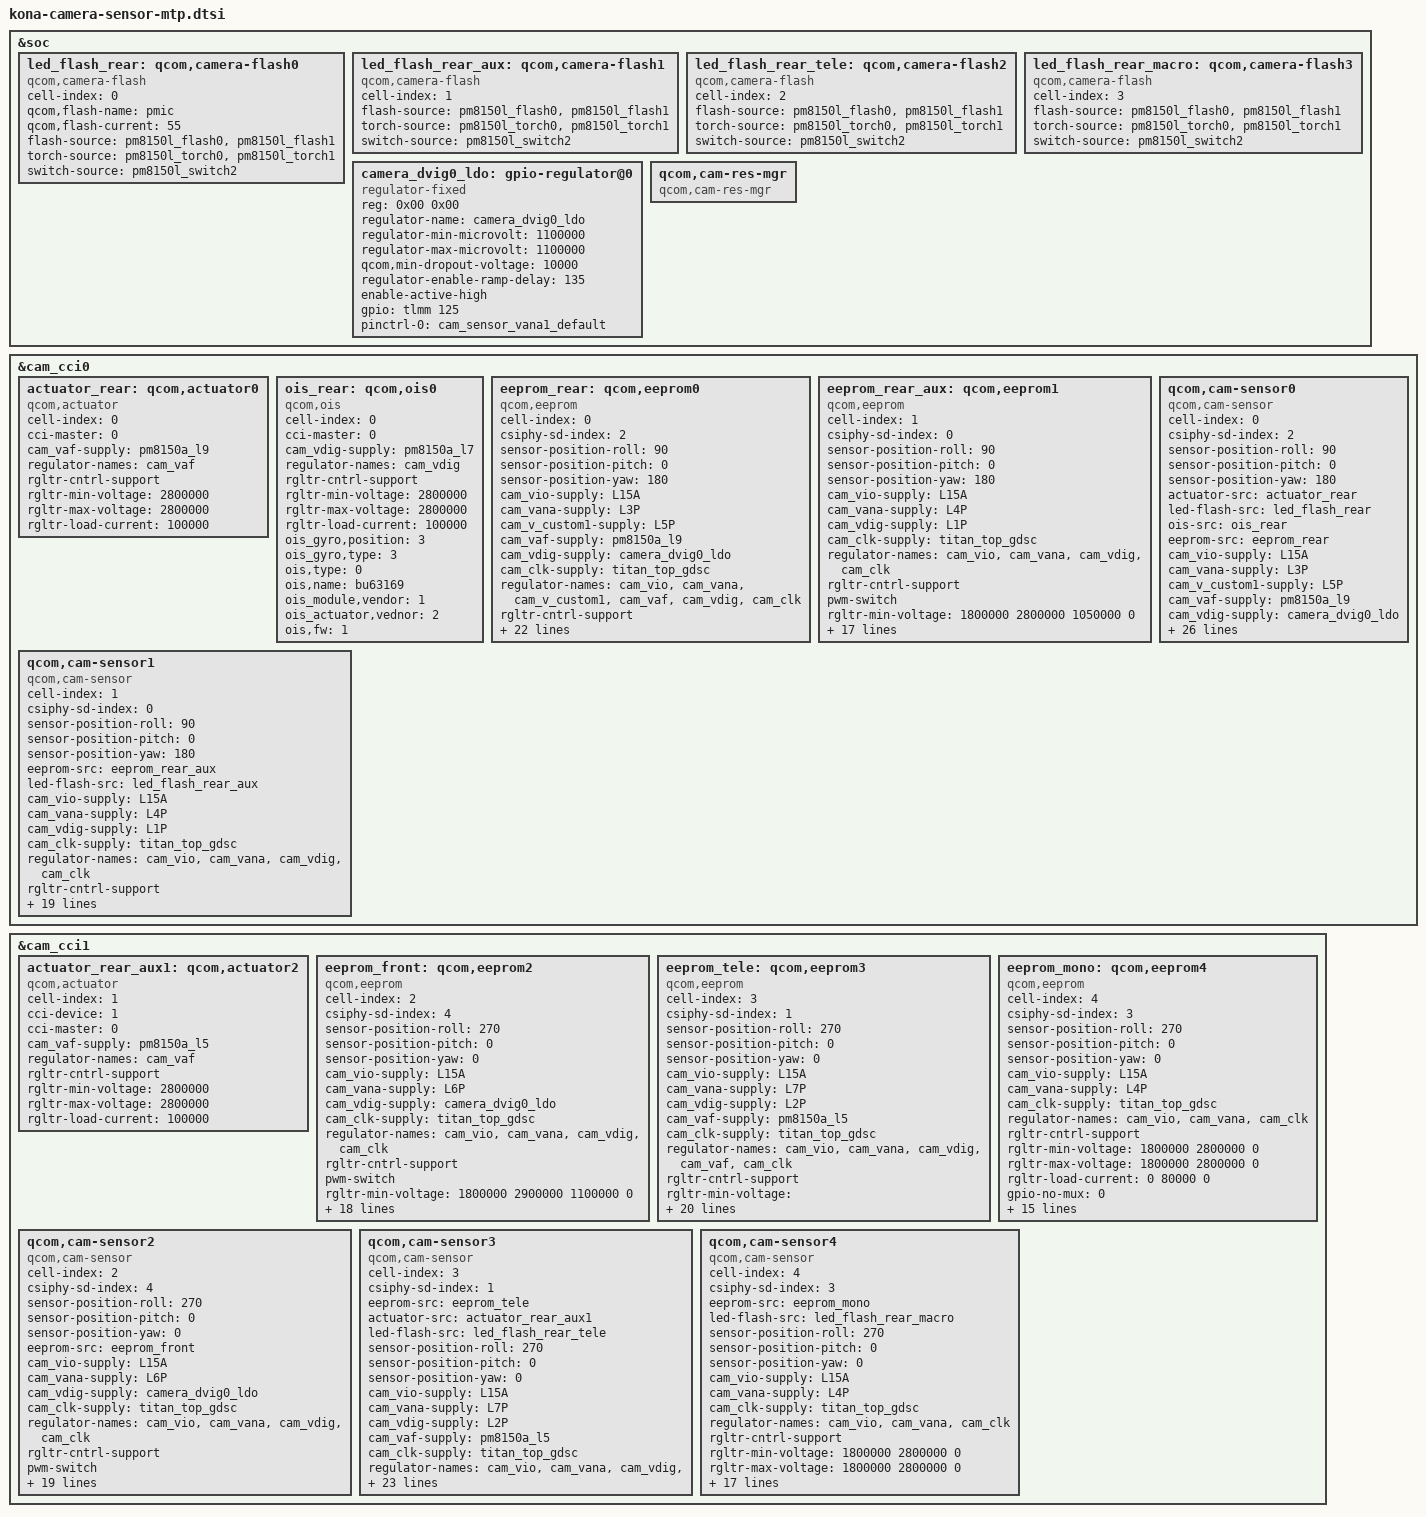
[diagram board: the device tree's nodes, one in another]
#include <dt-bindings/clock/qcom,camcc-kona.h>
/*#ifdef OPLUS_FEATURE_EDIT */
/*
&soc {
	led_flash_rear: qcom,camera-flash0 {
		cell-index = <0>;
		compatible = "qcom,camera-flash";
		flash-source = <&pm8150l_flash0 &pm8150l_flash1>;
		torch-source = <&pm8150l_torch0 &pm8150l_torch1>;
		switch-source = <&pm8150l_switch2>;
		status = "ok";
	};

	led_flash_rear_aux: qcom,camera-flash1 {
		cell-index = <1>;
		compatible = "qcom,camera-flash";
		flash-source = <&pm8150l_flash0 &pm8150l_flash1>;
		torch-source = <&pm8150l_torch0 &pm8150l_torch1>;
		switch-source = <&pm8150l_switch2>;
		status = "ok";
	};

	led_flash_triple_rear: qcom,camera-flash@4 {
		cell-index = <4>;
		compatible = "qcom,camera-flash";
		flash-source = <&pm8150l_flash0 &pm8150l_flash1>;
		torch-source = <&pm8150l_torch0 &pm8150l_torch1>;
		switch-source = <&pm8150l_switch2>;
		status = "ok";
	};

	led_flash_triple_rear_aux: qcom,camera-flash@5 {
		cell-index = <5>;
		compatible = "qcom,camera-flash";
		flash-source = <&pm8150l_flash0 &pm8150l_flash1>;
		torch-source = <&pm8150l_torch0 &pm8150l_torch1>;
		switch-source = <&pm8150l_switch2>;
		status = "ok";
	};

	led_flash_triple_rear_aux2: qcom,camera-flash@6 {
		cell-index = <6>;
		compatible = "qcom,camera-flash";
		flash-source = <&pm8150l_flash0 &pm8150l_flash1>;
		torch-source = <&pm8150l_torch0 &pm8150l_torch1>;
		switch-source = <&pm8150l_switch2>;
		status = "ok";
	};

	qcom,cam-res-mgr {
		compatible = "qcom,cam-res-mgr";
		status = "ok";
	};
};

&cam_cci0 {
	actuator_rear: qcom,actuator0 {
		cell-index = <0>;
		compatible = "qcom,actuator";
		cci-master = <0>;
		cam_vaf-supply = <&pm8150a_l7>;
		regulator-names = "cam_vaf";
		rgltr-cntrl-support;
		rgltr-min-voltage = <2856000>;
		rgltr-max-voltage = <3104000>;
		rgltr-load-current = <100000>;
	};

	actuator_rear_aux: qcom,actuator1 {
		cell-index = <1>;
		compatible = "qcom,actuator";
		cci-master = <1>;
		cam_vaf-supply = <&pm8150a_l7>;
		regulator-names = "cam_vaf";
		rgltr-cntrl-support;
		rgltr-min-voltage = <2856000>;
		rgltr-max-voltage = <3104000>;
		rgltr-load-current = <100000>;
	};

	actuator_triple_wide: qcom,actuator4 {
		cell-index = <4>;
		compatible = "qcom,actuator";
		cci-master = <0>;
		cam_vaf-supply = <&pm8150a_l7>;
		regulator-names = "cam_vaf";
		rgltr-cntrl-support;
		rgltr-min-voltage = <2856000>;
		rgltr-max-voltage = <3104000>;
		rgltr-load-current = <100000>;
	};

	actuator_triple_tele: qcom,actuator5 {
		cell-index = <5>;
		compatible = "qcom,actuator";
		cci-master = <1>;
		cam_vaf-supply = <&pm8150a_l7>;
		regulator-names = "cam_vaf";
		rgltr-cntrl-support;
		rgltr-min-voltage = <2856000>;
		rgltr-max-voltage = <3104000>;
		rgltr-load-current = <100000>;
	};

	eeprom_rear: qcom,eeprom0 {
		cell-index = <0>;
		compatible = "qcom,eeprom";
		cam_vio-supply = <&pm8009_l7>;
		cam_vana-supply = <&pm8009_l5>;
		cam_vdig-supply = <&pm8009_l1>;
		cam_clk-supply = <&titan_top_gdsc>;
		cam_vaf-supply = <&pm8150a_l7>;
		regulator-names = "cam_vio", "cam_vana", "cam_vdig",
			"cam_clk", "cam_vaf";
		rgltr-cntrl-support;
		rgltr-min-voltage = <1800000 2800000 1104000 0 2856000>;
		rgltr-max-voltage = <1800000 3000000 1104000 0 3104000>;
		rgltr-load-current = <120000 80000 1200000 0 100000>;
		gpio-no-mux = <0>;
		pinctrl-names = "cam_default", "cam_suspend";
		pinctrl-0 = <&cam_sensor_mclk0_active
				&cam_sensor_active_rear>;
		pinctrl-1 = <&cam_sensor_mclk0_suspend
				&cam_sensor_suspend_rear>;
		gpios = <&tlmm 94 0>,
			<&tlmm 93 0>;
		gpio-reset = <1>;
		gpio-req-tbl-num = <0 1>;
		gpio-req-tbl-flags = <1 0>;
		gpio-req-tbl-label = "CAMIF_MCLK0",
					"CAM_RESET0";
		sensor-position = <0>;
		sensor-mode = <0>;
		cci-master = <0>;
		status = "ok";
		clocks = <&clock_camcc CAM_CC_MCLK0_CLK>;
		clock-names = "cam_clk";
		clock-cntl-level = "turbo";
		clock-rates = <24000000>;
	};

	eeprom_rear_aux: qcom,eeprom1 {
		cell-index = <1>;
		compatible = "qcom,eeprom";
		cam_vdig-supply = <&pm8009_l2>;
		cam_vio-supply = <&pm8009_l7>;
		cam_vana-supply = <&pm8009_l6>;
		cam_clk-supply = <&titan_top_gdsc>;
		cam_vaf-supply = <&pm8150a_l7>;
		regulator-names = "cam_vio", "cam_vana", "cam_vdig",
			"cam_clk", "cam_vaf";
		rgltr-cntrl-support;
		rgltr-min-voltage = <1800000 2800000 1200000 0 2856000>;
		rgltr-max-voltage = <1800000 3000000 1200000 0 3104000>;
		rgltr-load-current = <120000 80000 1200000 0 100000>;
		gpio-no-mux = <0>;
		pinctrl-names = "cam_default", "cam_suspend";
		pinctrl-0 = <&cam_sensor_mclk1_active
				 &cam_sensor_active_rear_aux>;
		pinctrl-1 = <&cam_sensor_mclk1_suspend
				 &cam_sensor_suspend_rear_aux>;
		gpios = <&tlmm 95 0>,
			<&tlmm 92 0>;
		gpio-reset = <1>;
		gpio-req-tbl-num = <0 1>;
		gpio-req-tbl-flags = <1 0>;
		gpio-req-tbl-label = "CAMIF_MCLK1",
					"CAM_RESET1";
		sensor-position = <0>;
		sensor-mode = <0>;
		cci-master = <1>;
		status = "ok";
		clocks = <&clock_camcc CAM_CC_MCLK2_CLK>;
		clock-names = "cam_clk";
		clock-cntl-level = "turbo";
		clock-rates = <24000000>;
	};

	eeprom_triple_wide: qcom,eeprom4 {
		cell-index = <4>;
		compatible = "qcom,eeprom";
		cam_vio-supply = <&pm8009_l7>;
		cam_vana-supply = <&pm8009_l5>;
		cam_vdig-supply = <&pm8009_l1>;
		cam_clk-supply = <&titan_top_gdsc>;
		cam_vaf-supply = <&pm8150a_l7>;
		regulator-names = "cam_vio", "cam_vana", "cam_vdig",
			"cam_clk", "cam_vaf";
		rgltr-cntrl-support;
		rgltr-min-voltage = <1800000 2800000 1104000 0 2856000>;
		rgltr-max-voltage = <1800000 3000000 1104000 0 3104000>;
		rgltr-load-current = <120000 80000 1200000 0 0>;
		gpio-no-mux = <0>;
		pinctrl-names = "cam_default", "cam_suspend";
		pinctrl-0 = <&cam_sensor_mclk0_active
				&cam_sensor_active_rear>;
		pinctrl-1 = <&cam_sensor_mclk0_suspend
				&cam_sensor_suspend_rear>;
		gpios = <&tlmm 94 0>,
			<&tlmm 93 0>;
		gpio-reset = <1>;
		gpio-req-tbl-num = <0 1>;
		gpio-req-tbl-flags = <1 0>;
		gpio-req-tbl-label = "CAMIF_MCLK0",
					"CAM_RESET0";
		sensor-position = <0>;
		sensor-mode = <0>;
		cci-master = <0>;
		status = "ok";
		clocks = <&clock_camcc CAM_CC_MCLK0_CLK>;
		clock-names = "cam_clk";
		clock-cntl-level = "turbo";
		clock-rates = <24000000>;
	};

	eeprom_triple_tele: qcom,eeprom5 {
		cell-index = <5>;
		compatible = "qcom,eeprom";
		cam_vdig-supply = <&pm8009_l2>;
		cam_vio-supply = <&pm8009_l7>;
		cam_vana-supply = <&pm8009_l6>;
		cam_clk-supply = <&titan_top_gdsc>;
		cam_vaf-supply = <&pm8150a_l7>;
		regulator-names = "cam_vio", "cam_vana", "cam_vdig",
			"cam_clk", "cam_vaf";
		rgltr-cntrl-support;
		rgltr-min-voltage = <1800000 2800000 1200000 0 2856000>;
		rgltr-max-voltage = <1800000 3000000 1200000 0 3104000>;
		rgltr-load-current = <120000 80000 1200000 0 0>;
		gpio-no-mux = <0>;
		pinctrl-names = "cam_default", "cam_suspend";
		pinctrl-0 = <&cam_sensor_mclk1_active
				 &cam_sensor_active_rear_aux>;
		pinctrl-1 = <&cam_sensor_mclk1_suspend
				 &cam_sensor_suspend_rear_aux>;
		gpios = <&tlmm 95 0>,
			<&tlmm 92 0>;
		gpio-reset = <1>;
		gpio-req-tbl-num = <0 1>;
		gpio-req-tbl-flags = <1 0>;
		gpio-req-tbl-label = "CAMIF_MCLK1",
					"CAM_RESET1";
		sensor-position = <0>;
		sensor-mode = <0>;
		cci-master = <0>;
		status = "ok";
		clocks = <&clock_camcc CAM_CC_MCLK2_CLK>;
		clock-names = "cam_clk";
		clock-cntl-level = "turbo";
		clock-rates = <24000000>;
	};

	qcom,cam-sensor0 {
		cell-index = <0>;
		compatible = "qcom,cam-sensor";
		csiphy-sd-index = <0>;
		sensor-position-roll = <90>;
		sensor-position-pitch = <0>;
		sensor-position-yaw = <180>;
		actuator-src = <&actuator_rear>;
		led-flash-src = <&led_flash_rear>;
		eeprom-src = <&eeprom_rear>;
		cam_vio-supply = <&pm8009_l7>;
		cam_bob-supply = <&pm8150a_bob>;
		cam_vana-supply = <&pm8009_l5>;
		cam_vdig-supply = <&pm8009_l1>;
		cam_clk-supply = <&titan_top_gdsc>;
		regulator-names = "cam_vio", "cam_vana", "cam_vdig",
			"cam_clk", "cam_bob";
		rgltr-cntrl-support;
		pwm-switch;
		rgltr-min-voltage = <1800000 2800000 1104000 0 3008000>;
		rgltr-max-voltage = <1800000 3000000 1104000 0 3960000>;
		rgltr-load-current = <120000 80000 1200000 0 2000000>;
		gpio-no-mux = <0>;
		pinctrl-names = "cam_default", "cam_suspend";
		pinctrl-0 = <&cam_sensor_mclk0_active
				&cam_sensor_active_rear>;
		pinctrl-1 = <&cam_sensor_mclk0_suspend
				&cam_sensor_suspend_rear>;
		gpios = <&tlmm 94 0>,
			<&tlmm 93 0>;
		gpio-reset = <1>;
		gpio-req-tbl-num = <0 1>;
		gpio-req-tbl-flags = <1 0>;
		gpio-req-tbl-label = "CAMIF_MCLK0",
					"CAM_RESET0";
		sensor-mode = <0>;
		cci-master = <0>;
		status = "ok";
		clocks = <&clock_camcc CAM_CC_MCLK0_CLK>;
		clock-names = "cam_clk";
		clock-cntl-level = "turbo";
		clock-rates = <24000000>;
	};

	qcom,cam-sensor1 {
		cell-index = <1>;
		compatible = "qcom,cam-sensor";
		csiphy-sd-index = <1>;
		sensor-position-roll = <90>;
		sensor-position-pitch = <0>;
		sensor-position-yaw = <180>;
		eeprom-src = <&eeprom_rear_aux>;
		led-flash-src = <&led_flash_rear_aux>;
		actuator-src = <&actuator_rear_aux>;
		cam_bob-supply = <&pm8150a_bob>;
		cam_vdig-supply = <&pm8009_l2>;
		cam_vio-supply = <&pm8009_l7>;
		cam_vana-supply = <&pm8009_l6>;
		cam_clk-supply = <&titan_top_gdsc>;
		regulator-names = "cam_vio", "cam_vana", "cam_vdig",
			"cam_clk", "cam_bob";
		rgltr-cntrl-support;
		pwm-switch;
		rgltr-min-voltage = <1800000 2800000 1200000 0 3008000>;
		rgltr-max-voltage = <1800000 3000000 1200000 0 3960000>;
		rgltr-load-current = <120000 80000 1200000 0 2000000>;
		gpio-no-mux = <0>;
		pinctrl-names = "cam_default", "cam_suspend";
		pinctrl-0 = <&cam_sensor_mclk1_active
				&cam_sensor_active_rear_aux>;
		pinctrl-1 = <&cam_sensor_mclk1_suspend
				&cam_sensor_suspend_rear_aux>;
		gpios = <&tlmm 95 0>,
			<&tlmm 92 0>;
		gpio-reset = <1>;
		gpio-req-tbl-num = <0 1>;
		gpio-req-tbl-flags = <1 0>;
		gpio-req-tbl-label = "CAMIF_MCLK1",
					"CAM_RESET1";
		sensor-mode = <0>;
		cci-master = <1>;
		status = "ok";
		clocks = <&clock_camcc CAM_CC_MCLK1_CLK>;
		clock-names = "cam_clk";
		clock-cntl-level = "turbo";
		clock-rates = <24000000>;
	};

	qcom,cam-sensor4 {
		cell-index = <4>;
		compatible = "qcom,cam-sensor";
		csiphy-sd-index = <0>;
		sensor-position-roll = <90>;
		sensor-position-pitch = <0>;
		sensor-position-yaw = <180>;
		actuator-src = <&actuator_triple_wide>;
		led-flash-src = <&led_flash_triple_rear>;
		eeprom-src = <&eeprom_triple_wide>;
		cam_vio-supply = <&pm8009_l7>;
		cam_bob-supply = <&pm8150a_bob>;
		cam_vana-supply = <&pm8009_l5>;
		cam_vdig-supply = <&pm8009_l1>;
		cam_clk-supply = <&titan_top_gdsc>;
		regulator-names = "cam_vio", "cam_vana", "cam_vdig",
			"cam_clk", "cam_bob";
		rgltr-cntrl-support;
		pwm-switch;
		rgltr-min-voltage = <1800000 2800000 1104000 0 3008000>;
		rgltr-max-voltage = <1800000 3000000 1104000 0 3960000>;
		rgltr-load-current = <120000 80000 1200000 0 2000000>;
		gpio-no-mux = <0>;
		pinctrl-names = "cam_default", "cam_suspend";
		pinctrl-0 = <&cam_sensor_mclk0_active
				&cam_sensor_active_rear>;
		pinctrl-1 = <&cam_sensor_mclk0_suspend
				&cam_sensor_suspend_rear>;
		gpios = <&tlmm 94 0>,
			<&tlmm 93 0>;
		gpio-reset = <1>;
		gpio-req-tbl-num = <0 1>;
		gpio-req-tbl-flags = <1 0>;
		gpio-req-tbl-label = "CAMIF_MCLK0",
					"CAM_RESET0";
		sensor-mode = <0>;
		cci-master = <0>;
		status = "ok";
		clocks = <&clock_camcc CAM_CC_MCLK0_CLK>;
		clock-names = "cam_clk";
		clock-cntl-level = "turbo";
		clock-rates = <24000000>;
	};

	qcom,cam-sensor5 {
		cell-index = <5>;
		compatible = "qcom,cam-sensor";
		csiphy-sd-index = <1>;
		sensor-position-roll = <90>;
		sensor-position-pitch = <0>;
		sensor-position-yaw = <180>;
		eeprom-src = <&eeprom_triple_tele>;
		actuator-src = <&actuator_triple_tele>;
		led-flash-src = <&led_flash_triple_rear_aux>;
		cam_bob-supply = <&pm8150a_bob>;
		cam_vdig-supply = <&pm8009_l2>;
		cam_vio-supply = <&pm8009_l7>;
		cam_vana-supply = <&pm8009_l6>;
		cam_clk-supply = <&titan_top_gdsc>;
		regulator-names = "cam_vio", "cam_vana", "cam_vdig",
			"cam_clk", "cam_bob";
		rgltr-cntrl-support;
		pwm-switch;
		rgltr-min-voltage = <1800000 2800000 1200000 0 3008000>;
		rgltr-max-voltage = <1800000 3000000 1200000 0 3960000>;
		rgltr-load-current = <120000 80000 1200000 0 2000000>;
		gpio-no-mux = <0>;
		pinctrl-names = "cam_default", "cam_suspend";
		pinctrl-0 = <&cam_sensor_mclk1_active
				&cam_sensor_active_rear_aux>;
		pinctrl-1 = <&cam_sensor_mclk1_suspend
				&cam_sensor_suspend_rear_aux>;
		gpios = <&tlmm 95 0>,
			<&tlmm 92 0>;
		gpio-reset = <1>;
		gpio-req-tbl-num = <0 1>;
		gpio-req-tbl-flags = <1 0>;
		gpio-req-tbl-label = "CAMIF_MCLK1",
					"CAM_RESET1";
		sensor-mode = <0>;
		cci-master = <1>;
		status = "ok";
		clocks = <&clock_camcc CAM_CC_MCLK1_CLK>;
		clock-names = "cam_clk";
		clock-cntl-level = "turbo";
		clock-rates = <24000000>;
	};
};

&cam_cci1 {
	actuator_triple_uw: qcom,actuator6 {
		cell-index = <6>;
		compatible = "qcom,actuator";
		cci-master = <0>;
		cam_vaf-supply = <&pm8150a_l7>;
		regulator-names = "cam_vaf";
		rgltr-cntrl-support;
		rgltr-min-voltage = <2856000>;
		rgltr-max-voltage = <3104000>;
		rgltr-load-current = <100000>;
	};

	eeprom_front: qcom,eeprom2 {
		cell-index = <2>;
		compatible = "qcom,eeprom";
		cam_vio-supply = <&pm8009_l7>;
		cam_vana-supply = <&pm8009_l6>;
		cam_vdig-supply = <&pm8009_l3>;
		cam_clk-supply = <&titan_top_gdsc>;
		cam_vaf-supply = <&pm8150a_l7>;
		regulator-names = "cam_vio", "cam_vana", "cam_vdig",
			"cam_clk", "cam_vaf";
		rgltr-cntrl-support;
		rgltr-min-voltage = <1800000 2800000 1056000 0 2856000>;
		rgltr-max-voltage = <1800000 3000000 1056000 0 3104000>;
		rgltr-load-current = <120000 80000 1200000 0 100000>;
		gpio-no-mux = <0>;
		pinctrl-names = "cam_default", "cam_suspend";
		pinctrl-0 = <&cam_sensor_mclk2_active
				 &cam_sensor_active_rst2>;
		pinctrl-1 = <&cam_sensor_mclk2_suspend
				 &cam_sensor_suspend_rst2>;
		gpios = <&tlmm 96 0>,
			<&tlmm 78 0>;
		gpio-reset = <1>;
		gpio-req-tbl-num = <0 1>;
		gpio-req-tbl-flags = <1 0>;
		gpio-req-tbl-label = "CAMIF_MCLK2",
					"CAM_RESET2";
		sensor-position = <1>;
		sensor-mode = <0>;
		cci-master = <0>;
		status = "ok";
		clocks = <&clock_camcc CAM_CC_MCLK2_CLK>;
		clock-names = "cam_clk";
		clock-cntl-level = "turbo";
		clock-rates = <24000000>;
	};

	eeprom_triple_uw: qcom,eeprom6 {
		cell-index = <6>;
		compatible = "qcom,eeprom";
		cam_vio-supply = <&pm8009_l7>;
		cam_vana-supply = <&pm8009_l6>;
		cam_vdig-supply = <&pm8009_l3>;
		cam_clk-supply = <&titan_top_gdsc>;
		cam_vaf-supply = <&pm8150a_l7>;
		regulator-names = "cam_vio", "cam_vana", "cam_vdig",
			"cam_clk", "cam_vaf";
		rgltr-cntrl-support;
		rgltr-min-voltage = <1800000 2800000 1056000 0 2856000>;
		rgltr-max-voltage = <1800000 3000000 1056000 0 3104000>;
		rgltr-load-current = <120000 80000 1200000 0 100000>;
		gpio-no-mux = <0>;
		pinctrl-names = "cam_default", "cam_suspend";
		pinctrl-0 = <&cam_sensor_mclk2_active
				 &cam_sensor_active_rst2>;
		pinctrl-1 = <&cam_sensor_mclk2_suspend
				 &cam_sensor_suspend_rst2>;
		gpios = <&tlmm 96 0>,
			<&tlmm 78 0>;
		gpio-reset = <1>;
		gpio-req-tbl-num = <0 1>;
		gpio-req-tbl-flags = <1 0>;
		gpio-req-tbl-label = "CAMIF_MCLK2",
					"CAM_RESET2";
		sensor-position = <1>;
		sensor-mode = <0>;
		cci-master = <0>;
		status = "ok";
		clocks = <&clock_camcc CAM_CC_MCLK2_CLK>;
		clock-names = "cam_clk";
		clock-cntl-level = "turbo";
		clock-rates = <24000000>;
	};

	eeprom_tof: qcom,eeprom3 {
		cell-index = <3>;
		compatible = "qcom,eeprom";
		cam_vio-supply = <&pm8009_l7>;
		cam_vdig-supply = <&vreg_tof>;
		cam_clk-supply = <&titan_top_gdsc>;
		regulator-names = "cam_vio", "cam_vdig",
			"cam_clk";
		rgltr-cntrl-support;
		rgltr-min-voltage = <0 3600000 0>;
		rgltr-max-voltage = <0 3600000 0>;
		rgltr-load-current = <180000 120000 0>;
		gpio-no-mux = <0>;
		pinctrl-names = "cam_default", "cam_suspend";
		pinctrl-0 = <&cam_sensor_mclk3_active
			&cam_sensor_active_3>;
		pinctrl-1 = <&cam_sensor_mclk3_suspend
			&cam_sensor_suspend_3>;
		gpios = <&tlmm 97 0>,
			<&tlmm 163 0>;
		gpio-reset = <1>;
		gpio-req-tbl-num = <0 1>;
		gpio-req-tbl-flags = <1 0>;
		gpio-req-tbl-label = "CAMIF_MCLK3",
			"CAM_RESET3";
		sensor-position = <1>;
		sensor-mode = <0>;
		cci-master = <1>;
		status = "ok";
		clocks = <&clock_camcc CAM_CC_MCLK3_CLK>;
		clock-names = "cam_clk";
		clock-cntl-level = "turbo";
		clock-rates = <24000000>;
	};

	qcom,cam-sensor2 {
		cell-index = <2>;
		compatible = "qcom,cam-sensor";
		csiphy-sd-index = <2>;
		sensor-position-roll = <270>;
		sensor-position-pitch = <0>;
		sensor-position-yaw = <0>;
		eeprom-src = <&eeprom_front>;
		cam_vio-supply = <&pm8009_l7>;
		cam_bob-supply = <&pm8150a_bob>;
		cam_vana-supply = <&pm8009_l6>;
		cam_vdig-supply = <&pm8009_l3>;
		cam_clk-supply = <&titan_top_gdsc>;
		regulator-names = "cam_vio", "cam_vana", "cam_vdig",
			"cam_clk", "cam_bob";
		rgltr-cntrl-support;
		pwm-switch;
		rgltr-min-voltage = <1800000 2800000 1056000 0 3008000>;
		rgltr-max-voltage = <1800000 3000000 1056000 0 3960000>;
		rgltr-load-current = <120000 80000 1200000 0 2000000>;
		gpio-no-mux = <0>;
		pinctrl-names = "cam_default", "cam_suspend";
		pinctrl-0 = <&cam_sensor_mclk2_active
				 &cam_sensor_active_rst2>;
		pinctrl-1 = <&cam_sensor_mclk2_suspend
				 &cam_sensor_suspend_rst2>;
		gpios = <&tlmm 96 0>,
			<&tlmm 78 0>;
		gpio-reset = <1>;
		gpio-req-tbl-num = <0 1>;
		gpio-req-tbl-flags = <1 0>;
		gpio-req-tbl-label = "CAMIF_MCLK2",
					"CAM_RESET2";
		sensor-mode = <0>;
		cci-master = <0>;
		status = "ok";
		clocks = <&clock_camcc CAM_CC_MCLK2_CLK>;
		clock-names = "cam_clk";
		clock-cntl-level = "turbo";
		clock-rates = <24000000>;
	};

	qcom,cam-sensor3 {
		cell-index = <3>;
		compatible = "qcom,cam-sensor";
		csiphy-sd-index = <3>;
		eeprom-src = <&eeprom_tof>;
		sensor-position-roll = <270>;
		sensor-position-pitch = <0>;
		sensor-position-yaw = <0>;
		cam_vio-supply = <&pm8009_l7>;
		cam_vdig-supply = <&vreg_tof>;
		cam_clk-supply = <&titan_top_gdsc>;
		regulator-names = "cam_vio", "cam_vdig",
			"cam_clk";
		rgltr-cntrl-support;
		rgltr-min-voltage = <1800000 3600000 0>;
		rgltr-max-voltage = <1800000 3600000 0>;
		rgltr-load-current = <180000 120000 0>;
		gpio-no-mux = <0>;
		pinctrl-names = "cam_default", "cam_suspend";
		pinctrl-0 = <&cam_sensor_mclk3_active
				 &cam_sensor_active_3>;
		pinctrl-1 = <&cam_sensor_mclk3_suspend
				 &cam_sensor_suspend_3>;
		gpios = <&tlmm 97 0>,
			<&tlmm 163 0>;
		gpio-reset = <1>;
		gpio-req-tbl-num = <0 1>;
		gpio-req-tbl-flags = <1 0>;
		gpio-req-tbl-label = "CAMIF_MCLK3",
					"CAM_RESET3";
		sensor-mode = <0>;
		cci-master = <1>;
		status = "ok";
		clocks = <&clock_camcc CAM_CC_MCLK3_CLK>;
		clock-names = "cam_clk";
		clock-cntl-level = "turbo";
		clock-rates = <24000000>;
	};

	qcom,cam-sensor6 {
		cell-index = <6>;
		compatible = "qcom,cam-sensor";
		csiphy-sd-index = <2>;
		sensor-position-roll = <90>;
		sensor-position-pitch = <0>;
		sensor-position-yaw = <180>;
		eeprom-src = <&eeprom_triple_uw>;
		actuator-src = <&actuator_triple_uw>;
		led-flash-src = <&led_flash_triple_rear_aux2>;
		cam_vio-supply = <&pm8009_l7>;
		cam_bob-supply = <&pm8150a_bob>;
		cam_vana-supply = <&pm8009_l6>;
		cam_vdig-supply = <&pm8009_l3>;
		cam_clk-supply = <&titan_top_gdsc>;
		regulator-names = "cam_vio", "cam_vana", "cam_vdig",
			"cam_clk", "cam_bob";
		rgltr-cntrl-support;
		pwm-switch;
		rgltr-min-voltage = <1800000 2800000 1056000 0 3008000>;
		rgltr-max-voltage = <1800000 3000000 1056000 0 3960000>;
		rgltr-load-current = <120000 80000 1200000 0 2000000>;
		gpio-no-mux = <0>;
		pinctrl-names = "cam_default", "cam_suspend";
		pinctrl-0 = <&cam_sensor_mclk2_active
				 &cam_sensor_active_rst2>;
		pinctrl-1 = <&cam_sensor_mclk2_suspend
				 &cam_sensor_suspend_rst2>;
		gpios = <&tlmm 96 0>,
			<&tlmm 78 0>;
		gpio-reset = <1>;
		gpio-req-tbl-num = <0 1>;
		gpio-req-tbl-flags = <1 0>;
		gpio-req-tbl-label = "CAMIF_MCLK2",
					"CAM_RESET2";
		sensor-mode = <0>;
		cci-master = <0>;
		status = "ok";
		clocks = <&clock_camcc CAM_CC_MCLK2_CLK>;
		clock-names = "cam_clk";
		clock-cntl-level = "turbo";
		clock-rates = <24000000>;
	};
};
*/
&soc {
	led_flash_rear: qcom,camera-flash0 {
		cell-index = <0>;
		compatible = "qcom,camera-flash";
		qcom,flash-name = "pmic";
		qcom,flash-current = <55>;
		flash-source = <&pm8150l_flash0 &pm8150l_flash1>;
		torch-source = <&pm8150l_torch0 &pm8150l_torch1>;
		switch-source = <&pm8150l_switch2>;
		status = "ok";
	};

	led_flash_rear_aux: qcom,camera-flash1 {
		cell-index = <1>;
		compatible = "qcom,camera-flash";
		flash-source = <&pm8150l_flash0 &pm8150l_flash1>;
		torch-source = <&pm8150l_torch0 &pm8150l_torch1>;
		switch-source = <&pm8150l_switch2>;
		status = "ok";
	};

	led_flash_rear_tele: qcom,camera-flash2 {
		cell-index = <2>;
		compatible = "qcom,camera-flash";
		flash-source = <&pm8150l_flash0 &pm8150l_flash1>;
		torch-source = <&pm8150l_torch0 &pm8150l_torch1>;
		switch-source = <&pm8150l_switch2>;
		status = "ok";
	};

	led_flash_rear_macro: qcom,camera-flash3 {
		cell-index = <3>;
		compatible = "qcom,camera-flash";
		flash-source = <&pm8150l_flash0 &pm8150l_flash1>;
		torch-source = <&pm8150l_torch0 &pm8150l_torch1>;
		switch-source = <&pm8150l_switch2>;
		status = "ok";
	};

	camera_dvig0_ldo: gpio-regulator@0 {
		compatible = "regulator-fixed";
		reg = <0x00 0x00>;
		regulator-name = "camera_dvig0_ldo";
		regulator-min-microvolt = <1100000>;
		regulator-max-microvolt = <1100000>;
		qcom,min-dropout-voltage = <10000>;
		regulator-enable-ramp-delay = <135>;
		enable-active-high;
		gpio = <&tlmm 125 0>;
		pinctrl-names = "default";
		pinctrl-0 = <&cam_sensor_vana1_default>;
		//vin-supply = <&S5A>;
	};

	qcom,cam-res-mgr {
		compatible = "qcom,cam-res-mgr";
		status = "ok";
	};
};

&cam_cci0 {
	actuator_rear: qcom,actuator0 {
		cell-index = <0>;
		compatible = "qcom,actuator";
		cci-master = <0>;
		cam_vaf-supply = <&pm8150a_l9>;
		regulator-names = "cam_vaf";
		rgltr-cntrl-support;
		rgltr-min-voltage = <2800000>;
		rgltr-max-voltage = <2800000>;
		rgltr-load-current = <100000>;
	};

	ois_rear: qcom,ois0 {
		cell-index = <0>;
		compatible = "qcom,ois";
		cci-master = <0>;
		cam_vdig-supply = <&pm8150a_l7>;
		regulator-names = "cam_vdig";
		rgltr-cntrl-support;
		rgltr-min-voltage = <2800000>;
		rgltr-max-voltage = <2800000>;
		rgltr-load-current = <100000>;
		ois_gyro,position=<3>;
		ois_gyro,type=<3>;
		ois,type=<0>;
		ois,name="bu63169";
		ois_module,vendor=<1>;
		ois_actuator,vednor=<2>;
		ois,fw=<1>;
		status = "ok";
	};

	eeprom_rear: qcom,eeprom0 {
		cell-index = <0>;
		compatible = "qcom,eeprom";
		csiphy-sd-index = <2>;
		sensor-position-roll = <90>;
		sensor-position-pitch = <0>;
		sensor-position-yaw = <180>;
		cam_vio-supply = <&L15A>;
		cam_vana-supply = <&L3P>;
		cam_v_custom1-supply = <&L5P>;
		cam_vaf-supply = <&pm8150a_l9>;
		cam_vdig-supply = <&camera_dvig0_ldo>;
		cam_clk-supply = <&titan_top_gdsc>;
		regulator-names = "cam_vio", "cam_vana", "cam_v_custom1", "cam_vaf", "cam_vdig",
			"cam_clk";
		rgltr-cntrl-support;
		pwm-switch;
		rgltr-min-voltage = <1800000 2900000 1800000 2800000 1100000 0>;
		rgltr-max-voltage = <1800000 2900000 1800000 2800000 1100000 0>;
		rgltr-load-current = <0 80000 80000 80000 105000 0>;
		gpio-no-mux = <0>;
		pinctrl-names = "cam_default", "cam_suspend";
		pinctrl-0 = <&cam_sensor_mclk0_active
				&cam_sensor_active_rear>;
		pinctrl-1 = <&cam_sensor_mclk0_suspend
				&cam_sensor_suspend_rear>;
		gpios = <&tlmm 94 0>,
			<&tlmm 90 0>;
		gpio-reset = <1>;
		gpio-req-tbl-num = <0 1>;
		gpio-req-tbl-flags = <1 0>;
		gpio-req-tbl-label = "CAMIF_MCLK0",
					"CAM_RESET0";
		sensor-mode = <0>;
		cci-master = <0>;
		status = "ok";
		clocks = <&clock_camcc CAM_CC_MCLK0_CLK>;
		clock-names = "cam_clk";
		clock-cntl-level = "turbo";
		clock-rates = <19200000>;
	};

	eeprom_rear_aux: qcom,eeprom1 {
		cell-index = <1>;
		compatible = "qcom,eeprom";
		csiphy-sd-index = <0>;
		sensor-position-roll = <90>;
		sensor-position-pitch = <0>;
		sensor-position-yaw = <180>;
		cam_vio-supply = <&L15A>;
		cam_vana-supply = <&L4P>;
		cam_vdig-supply = <&L1P>;
		cam_clk-supply = <&titan_top_gdsc>;
		regulator-names = "cam_vio", "cam_vana", "cam_vdig",
			"cam_clk";
		rgltr-cntrl-support;
		pwm-switch;
		rgltr-min-voltage = <1800000 2800000 1050000 0>;
		rgltr-max-voltage = <1800000 2800000 1050000 0>;
		rgltr-load-current = <0 80000 105000 0>;
		gpio-no-mux = <0>;
		pinctrl-names = "cam_default", "cam_suspend";
		pinctrl-0 = <&cam_sensor_mclk1_active
				&cam_sensor_active_rst2>;
		pinctrl-1 = <&cam_sensor_mclk1_suspend
				&cam_sensor_suspend_rst2>;
		gpios = <&tlmm 95 0>,
			<&tlmm 78 0>;
		gpio-reset = <1>;
		gpio-req-tbl-num = <0 1>;
		gpio-req-tbl-flags = <1 0>;
		gpio-req-tbl-label = "CAMIF_MCLK1",
					"CAM_RESET1";
		sensor-mode = <0>;
		cci-master = <1>;
		status = "ok";
		clocks = <&clock_camcc CAM_CC_MCLK1_CLK>;
		clock-names = "cam_clk";
		clock-cntl-level = "turbo";
		clock-rates = <19200000>;
	};

    /*IMX686*/
	qcom,cam-sensor0 {
		cell-index = <0>;
		compatible = "qcom,cam-sensor";
		csiphy-sd-index = <2>;
		sensor-position-roll = <90>;
		sensor-position-pitch = <0>;
		sensor-position-yaw = <180>;
		actuator-src = <&actuator_rear>;
		led-flash-src = <&led_flash_rear>;
		ois-src = <&ois_rear>;
		eeprom-src = <&eeprom_rear>;
		cam_vio-supply = <&L15A>;
		cam_vana-supply = <&L3P>;
		cam_v_custom1-supply = <&L5P>;
		cam_vaf-supply = <&pm8150a_l9>;
		cam_vdig-supply = <&camera_dvig0_ldo>;
		cam_clk-supply = <&titan_top_gdsc>;
		regulator-names = "cam_vio", "cam_vana", "cam_v_custom1", "cam_vaf", "cam_vdig",
			"cam_clk";
		rgltr-cntrl-support;
		pwm-switch;
		rgltr-min-voltage = <1800000 2900000 1800000 2800000 1100000 0>;
		rgltr-max-voltage = <1800000 2900000 1800000 2800000 1100000 0>;
		rgltr-load-current = <0 80000 80000 80000 105000 0>;
		gpio-no-mux = <0>;
		pinctrl-names = "cam_default", "cam_suspend";
		pinctrl-0 = <&cam_sensor_mclk0_active
				&cam_sensor_active_rear>;
		pinctrl-1 = <&cam_sensor_mclk0_suspend
				&cam_sensor_suspend_rear>;
		gpios = <&tlmm 94 0>,
			<&tlmm 90 0>;
		gpio-reset = <1>;
		gpio-req-tbl-num = <0 1>;
		gpio-req-tbl-flags = <1 0>;
		gpio-req-tbl-label = "CAMIF_MCLK0",
					"CAM_RESET0";
		sensor-mode = <0>;
		cci-master = <0>;
		status = "ok";
		clocks = <&clock_camcc CAM_CC_MCLK0_CLK>;
		clock-names = "cam_clk";
		clock-cntl-level = "turbo";
		clock-rates = <19200000>;
	};
    /*imx481*/
	qcom,cam-sensor1 {
		cell-index = <1>;
		compatible = "qcom,cam-sensor";
		csiphy-sd-index = <0>;
		sensor-position-roll = <90>;
		sensor-position-pitch = <0>;
		sensor-position-yaw = <180>;
		eeprom-src = <&eeprom_rear_aux>;
		led-flash-src = <&led_flash_rear_aux>;
		cam_vio-supply = <&L15A>;
		cam_vana-supply = <&L4P>;
		cam_vdig-supply = <&L1P>;
		cam_clk-supply = <&titan_top_gdsc>;
		regulator-names = "cam_vio", "cam_vana", "cam_vdig",
			"cam_clk";
		rgltr-cntrl-support;
		pwm-switch;
		rgltr-min-voltage = <1800000 2800000 1050000 0>;
		rgltr-max-voltage = <1800000 2800000 1050000 0>;
		rgltr-load-current = <0 80000 105000 0>;
		gpio-no-mux = <0>;
		pinctrl-names = "cam_default", "cam_suspend";
		pinctrl-0 = <&cam_sensor_mclk1_active
				&cam_sensor_active_rst2>;
		pinctrl-1 = <&cam_sensor_mclk1_suspend
				&cam_sensor_suspend_rst2>;
		gpios = <&tlmm 95 0>,
			<&tlmm 78 0>;
		gpio-reset = <1>;
		gpio-req-tbl-num = <0 1>;
		gpio-req-tbl-flags = <1 0>;
		gpio-req-tbl-label = "CAMIF_MCLK1",
					"CAM_RESET1";
		sensor-mode = <0>;
		cci-master = <1>;
		status = "ok";
		clocks = <&clock_camcc CAM_CC_MCLK1_CLK>;
		clock-names = "cam_clk";
		clock-cntl-level = "turbo";
		clock-rates = <19200000>;
	};
};
// ccix descrip device
&cam_cci1 {
	actuator_rear_aux1: qcom,actuator2 {
		cell-index = <1>;
		compatible = "qcom,actuator";
		cci-device = <1>;
		cci-master = <0>;
		cam_vaf-supply = <&pm8150a_l5>;
		regulator-names = "cam_vaf";
		rgltr-cntrl-support;
		rgltr-min-voltage = <2800000>;
		rgltr-max-voltage = <2800000>;
		rgltr-load-current = <100000>;
	};

	eeprom_front: qcom,eeprom2 {
		cell-index = <2>;
		compatible = "qcom,eeprom";
		csiphy-sd-index = <4>;
		sensor-position-roll = <270>;
		sensor-position-pitch = <0>;
		sensor-position-yaw = <0>;
		cam_vio-supply = <&L15A>;
		cam_vana-supply = <&L6P>;
		cam_vdig-supply = <&camera_dvig0_ldo>;
		cam_clk-supply = <&titan_top_gdsc>;
		regulator-names = "cam_vio", "cam_vana", "cam_vdig",
			"cam_clk";
		rgltr-cntrl-support;
		pwm-switch;
		rgltr-min-voltage = <1800000 2900000 1100000 0>;
		rgltr-max-voltage = <1800000 2900000 1100000 0>;
		rgltr-load-current = <0 80000 105000 0>;
		gpio-no-mux = <0>;
		pinctrl-names = "cam_default", "cam_suspend";
		pinctrl-0 = <&cam_sensor_mclk2_active
				 &cam_sensor_active_rear_aux>;
		pinctrl-1 = <&cam_sensor_mclk2_suspend
				 &cam_sensor_suspend_rear_aux>;
		gpios = <&tlmm 96 0>,
			<&tlmm 76 0>;
		gpio-reset = <1>;
		gpio-req-tbl-num = <0 1>;
		gpio-req-tbl-flags = <1 0>;
		gpio-req-tbl-label = "CAMIF_MCLK2",
					"CAM_RESET2";
		sensor-mode = <0>;
		cci-device = <0>;
		cci-master = <1>;
		status = "ok";
		clocks = <&clock_camcc CAM_CC_MCLK2_CLK>;
		clock-names = "cam_clk";
		clock-cntl-level = "turbo";
		clock-rates = <19200000>;
	};

	eeprom_tele: qcom,eeprom3 {
		cell-index = <3>;
		compatible = "qcom,eeprom";
		csiphy-sd-index = <1>;
		sensor-position-roll = <270>;
		sensor-position-pitch = <0>;
		sensor-position-yaw = <0>;
		cam_vio-supply = <&L15A>;
		cam_vana-supply = <&L7P>;
		cam_vdig-supply = <&L2P>;
		cam_vaf-supply = <&pm8150a_l5>;
		cam_clk-supply = <&titan_top_gdsc>;
		regulator-names = "cam_vio", "cam_vana", "cam_vdig", "cam_vaf",
			"cam_clk";
		rgltr-cntrl-support;
		rgltr-min-voltage = <1800000 2800000 1050000 2800000 0>;
		rgltr-max-voltage = <1800000 2800000 1050000 2800000 0>;
		rgltr-load-current = <0 80000 105000 80000 0>;
		gpio-no-mux = <0>;
		pinctrl-names = "cam_default", "cam_suspend";
		pinctrl-0 = <&cam_sensor_mclk4_active
				 &cam_sensor_active_3>;
		pinctrl-1 = <&cam_sensor_mclk4_suspend
				 &cam_sensor_suspend_3>;
		gpios = <&tlmm 98 0>,
			<&tlmm 92 0>;
		gpio-reset = <1>;
		gpio-req-tbl-num = <0 1>;
		gpio-req-tbl-flags = <1 0>;
		gpio-req-tbl-label = "CAMIF_MCLK4",
					"CAM_RESET3";
		sensor-mode = <0>;
		cci-device = <1>;
		cci-master = <0>;
		status = "ok";
		clocks = <&clock_camcc CAM_CC_MCLK4_CLK>;
		clock-names = "cam_clk";
		clock-cntl-level = "turbo";
		clock-rates = <19200000>;
	};

    eeprom_mono: qcom,eeprom4 {
		cell-index = <4>;
		compatible = "qcom,eeprom";
		csiphy-sd-index = <3>;
		sensor-position-roll = <270>;
		sensor-position-pitch = <0>;
		sensor-position-yaw = <0>;
		cam_vio-supply = <&L15A>;
		cam_vana-supply = <&L4P>;
		cam_clk-supply = <&titan_top_gdsc>;
		regulator-names = "cam_vio", "cam_vana",
			"cam_clk";
		rgltr-cntrl-support;
		rgltr-min-voltage = <1800000 2800000 0>;
		rgltr-max-voltage = <1800000 2800000 0>;
		rgltr-load-current = <0 80000 0>;
		gpio-no-mux = <0>;
		pinctrl-names = "cam_default", "cam_suspend";
		pinctrl-0 = <&cam_sensor_mclk3_active
				 &cam_sensor_active_5>;
		pinctrl-1 = <&cam_sensor_mclk3_suspend
				 &cam_sensor_suspend_5>;
		gpios = <&tlmm 97 0>,
			<&tlmm 130 0>;
		gpio-reset = <1>;
		gpio-req-tbl-num = <0 1>;
		gpio-req-tbl-flags = <1 0>;
		gpio-req-tbl-label = "CAMIF_MCLK3",
					"CAM_RESET5";
		sensor-mode = <0>;
		cci-device = <1>;
		cci-master = <0>;
		status = "ok";
		clocks = <&clock_camcc CAM_CC_MCLK3_CLK>;
		clock-names = "cam_clk";
		clock-cntl-level = "turbo";
		clock-rates = <19200000>;
	};

    /*imx616*/
	qcom,cam-sensor2 {
		cell-index = <2>;
		compatible = "qcom,cam-sensor";
		csiphy-sd-index = <4>;
		sensor-position-roll = <270>;
		sensor-position-pitch = <0>;
		sensor-position-yaw = <0>;
		eeprom-src = <&eeprom_front>;
		cam_vio-supply = <&L15A>;
		cam_vana-supply = <&L6P>;
		cam_vdig-supply = <&camera_dvig0_ldo>;
		cam_clk-supply = <&titan_top_gdsc>;
		regulator-names = "cam_vio", "cam_vana", "cam_vdig",
			"cam_clk";
		rgltr-cntrl-support;
		pwm-switch;
		rgltr-min-voltage = <1800000 2900000 1100000 0>;
		rgltr-max-voltage = <1800000 2900000 1100000 0>;
		rgltr-load-current = <0 80000 105000 0>;
		gpio-no-mux = <0>;
		pinctrl-names = "cam_default", "cam_suspend";
		pinctrl-0 = <&cam_sensor_mclk2_active
				 &cam_sensor_active_rear_aux>;
		pinctrl-1 = <&cam_sensor_mclk2_suspend
				 &cam_sensor_suspend_rear_aux>;
		gpios = <&tlmm 96 0>,
			<&tlmm 76 0>;
		gpio-reset = <1>;
		gpio-req-tbl-num = <0 1>;
		gpio-req-tbl-flags = <1 0>;
		gpio-req-tbl-label = "CAMIF_MCLK2",
					"CAM_RESET2";
		sensor-mode = <0>;
		cci-device = <0>;
		cci-master = <1>;
		status = "ok";
		clocks = <&clock_camcc CAM_CC_MCLK2_CLK>;
		clock-names = "cam_clk";
		clock-cntl-level = "turbo";
		clock-rates = <19200000>;
	};
    /*3m5*/
	qcom,cam-sensor3 {
		cell-index = <3>;
		compatible = "qcom,cam-sensor";
		csiphy-sd-index = <1>;
		eeprom-src = <&eeprom_tele>;
		actuator-src = <&actuator_rear_aux1>;
		led-flash-src = <&led_flash_rear_tele>;
		sensor-position-roll = <270>;
		sensor-position-pitch = <0>;
		sensor-position-yaw = <0>;
		cam_vio-supply = <&L15A>;
		cam_vana-supply = <&L7P>;
		cam_vdig-supply = <&L2P>;
		cam_vaf-supply = <&pm8150a_l5>;
		cam_clk-supply = <&titan_top_gdsc>;
		regulator-names = "cam_vio", "cam_vana", "cam_vdig", "cam_vaf",
			"cam_clk";
		rgltr-cntrl-support;
		rgltr-min-voltage = <1800000 2800000 1050000 2800000 0>;
		rgltr-max-voltage = <1800000 2800000 1050000 2800000 0>;
		rgltr-load-current = <0 80000 105000 80000 0>;
		gpio-no-mux = <0>;
		pinctrl-names = "cam_default", "cam_suspend";
		pinctrl-0 = <&cam_sensor_mclk4_active
				 &cam_sensor_active_3>;
		pinctrl-1 = <&cam_sensor_mclk4_suspend
				 &cam_sensor_suspend_3>;
		gpios = <&tlmm 98 0>,
			<&tlmm 92 0>;
		gpio-reset = <1>;
		gpio-req-tbl-num = <0 1>;
		gpio-req-tbl-flags = <1 0>;
		gpio-req-tbl-label = "CAMIF_MCLK4",
					"CAM_RESET3";
		sensor-mode = <0>;
		cci-device = <1>;
		cci-master = <0>;
		status = "ok";
		clocks = <&clock_camcc CAM_CC_MCLK4_CLK>;
		clock-names = "cam_clk";
		clock-cntl-level = "turbo";
		clock-rates = <19200000>;
	};
    /*ov02b*/
    qcom,cam-sensor4 {
		cell-index = <4>;
		compatible = "qcom,cam-sensor";
		csiphy-sd-index = <3>;
		eeprom-src = <&eeprom_mono>;
		led-flash-src = <&led_flash_rear_macro>;
		sensor-position-roll = <270>;
		sensor-position-pitch = <0>;
		sensor-position-yaw = <0>;
		cam_vio-supply = <&L15A>;
		cam_vana-supply = <&L4P>;
		cam_clk-supply = <&titan_top_gdsc>;
		regulator-names = "cam_vio", "cam_vana",
			"cam_clk";
		rgltr-cntrl-support;
		rgltr-min-voltage = <1800000 2800000 0>;
		rgltr-max-voltage = <1800000 2800000 0>;
		rgltr-load-current = <0 80000 0>;
		gpio-no-mux = <0>;
		pinctrl-names = "cam_default", "cam_suspend";
		pinctrl-0 = <&cam_sensor_mclk3_active
				 &cam_sensor_active_5>;
		pinctrl-1 = <&cam_sensor_mclk3_suspend
				 &cam_sensor_suspend_5>;
		gpios = <&tlmm 97 0>,
			<&tlmm 130 0>;
		gpio-reset = <1>;
		gpio-req-tbl-num = <0 1>;
		gpio-req-tbl-flags = <1 0>;
		gpio-req-tbl-label = "CAMIF_MCLK3",
					"CAM_RESET5";
		sensor-mode = <0>;
		cci-device = <1>;
		cci-master = <0>;
		status = "ok";
		clocks = <&clock_camcc CAM_CC_MCLK3_CLK>;
		clock-names = "cam_clk";
		clock-cntl-level = "turbo";
		clock-rates = <19200000>;
	};
};
/*endif */
